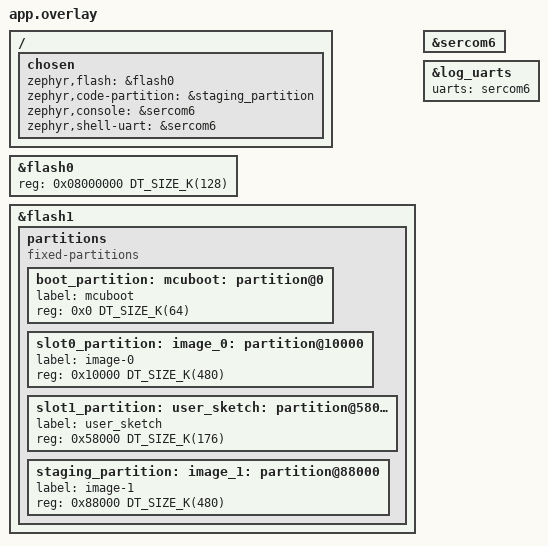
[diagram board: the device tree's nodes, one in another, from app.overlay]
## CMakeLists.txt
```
# SPDX-License-Identifier: Apache-2.0

cmake_minimum_required(VERSION 3.20.0)

# Resolve NORMALIZED_BOARD_TARGET so the board variant overlay can be named.
#
# Both overlays are listed explicitly, variant first, so app.overlay is last and
# therefore wins: the variants set `chosen { zephyr,console = ... }` themselves
# (sercom6 on both assemblies) and this sample restates it rather than relying
# on that. Ordering here is plain list order -- deliberately not the
# DTC_OVERLAY_FILE-vs-EXTRA_DTC_OVERLAY_FILE concatenation detail, which is an
# undocumented Zephyr implementation detail that fails silently if it changes.
find_package(Zephyr REQUIRED HINTS $ENV{ZEPHYR_BASE} COMPONENTS yaml boards)
set(DTC_OVERLAY_FILE
	${CMAKE_CURRENT_LIST_DIR}/../../variants/${NORMALIZED_BOARD_TARGET}/${NORMALIZED_BOARD_TARGET}.overlay
	${CMAKE_CURRENT_LIST_DIR}/app.overlay
)

find_package(Zephyr REQUIRED HINTS $ENV{ZEPHYR_BASE})
project(usb-dfu)

include(${ZEPHYR_BASE}/samples/subsys/usb/common/common.cmake)
FILE(GLOB app_sources src/*.c)
target_sources(app PRIVATE ${app_sources})

# <dfu_cookie.h> - the address/magic contract this sample shares with the
# loader and sketch. It lives beside the overlay that declares the reserved
# region so the two can never drift apart. The variants directory is not
# otherwise on the include path here: the core's top-level CMakeLists adds it,
# but only when CONFIG_ARDUINO_API is set, which this sample deliberately does
# not enable.
target_include_directories(app PRIVATE
	${CMAKE_CURRENT_LIST_DIR}/../../variants/arduino_nano_xl_link_pic32ck1025gc01144
	${CMAKE_CURRENT_LIST_DIR}/../../loader/boards/arduino_nano_xl_link_pic32ck1025gc01144/bfm
)

# The BFM writer and the Dual-Boot slot management moved to loader/boards/ so
# the loader can use them too - they are SoC behaviour, not sample behaviour.
# (They are NOT under variants/: arduino-cli scans that directory recursively
# when building a sketch, so anything there is compiled into every sketch.)
# They are added here rather than guarded internally, so "is this file in this
# image" is a build-system question.
target_sources_ifdef(CONFIG_APP_BFM_FLASH app PRIVATE
	${CMAKE_CURRENT_LIST_DIR}/../../loader/boards/arduino_nano_xl_link_pic32ck1025gc01144/bfm/bfm_flash.c
	${CMAKE_CURRENT_LIST_DIR}/../../loader/boards/arduino_nano_xl_link_pic32ck1025gc01144/bfm/bfm_boot.c
)
```

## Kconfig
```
# Copyright (c) 2023 Nordic Semiconductor ASA
# SPDX-License-Identifier: Apache-2.0

menu "USB DFU sample options"

config APP_USB_DFU_USE_FLASH_BACKEND
	select FLASH
	select FLASH_MAP
	select STREAM_FLASH
	select IMG_MANAGER
	select IMG_ERASE_PROGRESSIVELY
	bool "Option to clear the flash area before mounting"
	help
	  Use this to force an existing file system to be created.

if APP_USB_DFU_USE_FLASH_BACKEND

config USBD_DFU_FLASH
	default y

config USBD_DFU_FLASH_SLOT0
	default y

config USBD_DFU_FLASH_SLOT1
	default y

endif

config APP_BFM_FLASH
	bool
	help
	  Build src/bfm_flash.c, the on-chip writer for the Boot Flash Memory at
	  0x08000000. No prompt: it is selected by whatever needs it, and there
	  is nothing to gain from turning it on alone.

config APP_BFM_SELFTEST
	bool "Self-test the on-chip BFM writer at boot"
	select APP_BFM_FLASH
	select PRINTK
	select CONSOLE
	select UART_CONSOLE
	help
	  Program two scratch BFM pages from the running image at boot and
	  report on sercom6 (header J4, TX=PA00/RX=PA01) at 115200, proving that
	  BFM can be written with no SWD probe attached.

	  Both write-protect registers are exercised: one page in Lower Boot
	  (LBWP) and one in Upper Boot (UBWP). Neither page is part of this
	  image, so a failure destroys nothing -- but read the pages back from
	  the host before believing the console, because a silently dropped
	  write is exactly what this is testing for.

	  Development aid. Leave it off in anything you flash to a user's board.

config APP_BFM_DFU_ALT
	bool "Expose the spare BFM slot as a DFU alternate setting"
	default y
	select APP_BFM_FLASH
	help
	  Add alternate setting 2, "bfm_spare", so this bootloader can be
	  updated over USB with no SWD probe:

	      dfu-util -a 2 -D dfu_boot.bin

	  The image is written to the Dual-Boot slot that is NOT running, at
	  0x08010000, then verified and promoted by raising its sequence number
	  so the Boot ROM maps it to 0x08000000 at the next reset. A failure at
	  any point before that promotion leaves the board booting exactly what
	  it booted before.

	  The image must fit the 64 KB slot, and it must be linked for
	  0x08000000 -- which is where it will run once promoted, not where it
	  is written.

config APP_BFM_AB_TEST
	bool "Promote the spare BFM slot at boot (destructive, dev only)"
	select APP_BFM_FLASH
	help
	  At boot, if the spare BFM slot at 0x08010000 holds a valid-looking
	  image, raise its Dual-Boot sequence number so the Boot ROM maps it to
	  0x08000000 on the next reset. This is the real promotion path, run
	  unconditionally -- it exists to prove the swap on hardware.

	  Flash this build into the ACTIVE slot and a plain build into the
	  spare. After one reset the plain build runs and nothing promotes
	  again. Putting this build in BOTH slots makes the board ping-pong
	  between them forever.

	  It rewrites a CFM User CFG page, which also carries WDT and ECC
	  configuration. Never enable it in anything you ship.

endmenu

# Source common USB sample options used to initialize new experimental USB
# device stack. The scope of these options is limited to USB samples in project
# tree, you cannot use them in your own application.
source "samples/subsys/usb/common/Kconfig.sample_usbd"

source "Kconfig.zephyr"
```

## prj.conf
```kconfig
# ---------------------------------------------------------------------------
# USB DFU bootloader -- core function
# ---------------------------------------------------------------------------
CONFIG_SERIAL=y
CONFIG_USB_DEVICE_STACK_NEXT=y
CONFIG_USB_DEVICE_PRODUCT="Arduino Nano XL Link"
CONFIG_USB_DEVICE_MANUFACTURER="Arduino"
CONFIG_USB_DEVICE_VID=0x2341
CONFIG_USB_DEVICE_PID=0x007e
CONFIG_CDC_ACM_SERIAL_INITIALIZE_AT_BOOT=n
CONFIG_CDC_ACM_SERIAL_ENABLE_AT_BOOT=n
CONFIG_USBD_DFU=y
CONFIG_APP_USB_DFU_USE_FLASH_BACKEND=y
# src/dfu_images.c is an app-local copy of the in-tree flash backend that also
# feeds dfu_activity_notify(); see the comment at the top of that file. Only one
# of the two may register slot0_image/slot1_image.
CONFIG_USBD_DFU_FLASH=n
CONFIG_USBD_DFU_FLASH_SLOT0=n
CONFIG_USBD_DFU_FLASH_SLOT1=n

# ---------------------------------------------------------------------------
# Image placement: this image links at the BFM base (0x08000000) directly --
# see app.overlay.
# ---------------------------------------------------------------------------
# Its vector table is therefore already on the hardware reset address, so
# relocating rom_start there would collide with the image itself.
#
# Per-image override on purpose; do NOT try to hoist it into the SoC
# Kconfig.defconfig, which has `default n if BOOTLOADER_MCUBOOT || MCUBOOT`.
# That default is correct for Microchip's layout, where MCUboot lives in BFM at
# flash0 offset 0 (so it already owns the reset vector) and images under it are
# chainloaded from PFM. This board deviates -- MCUboot sits in PFM and needs
# =y for a BFM stub (see extra/mcuboot/nano_xl_link_monica.conf), while this
# sample *is* the BFM resident and needs =n. "Which image owns 0x08000000" is
# genuinely a per-image fact here, so it belongs in each image's own conf.
CONFIG_ROMSTART_RELOCATION_ROM=n
CONFIG_USE_DT_CODE_PARTITION=n

# Bound the image to ONE Dual-Boot slot, not the whole 128 KB of BFM.
#
# BFM is two 64 KB slots, one per panel, and the Boot ROM maps the one with the
# higher sequence number to 0x08000000 (DS 31.2.17.2). That is what makes the
# probe-less self-update in CONFIG_APP_BFM_DFU_ALT safe against power loss --
# but it only works while the image fits a single slot. An image spanning both
# would overwrite the spare copy it is supposed to fall back on.
#
# This is deliberately enforced by the linker rather than a build-time check:
# overflowing it must fail here, loudly, and not at promotion time on a user's
# board. If it ever does overflow, shrink the image; do not raise this.
CONFIG_FLASH_LOAD_SIZE=0x10000

# ---------------------------------------------------------------------------
# Stack and buffer sizing -- NOT optional. These fix real DFU download
# failures, and they are deliberately sized for the worst case of the debug
# block at the bottom being ENABLED, so turning logging on needs no retuning.
# ---------------------------------------------------------------------------

# The DFU download handler runs on the USB device stack thread, not main:
# dfu_flash_write() -> flash_img_buffered_write() -> stream_flash_erase_to_append()
# -> flash_mchp_erase() -> exec_flash_operation() all nest there, and with
# CONFIG_LOG_MODE_IMMEDIATE every log line adds a blocking formatter frame on top.
# The 1024 B default overflows on the first erase (USAGE FAULT / stack overflow),
# which surfaces to the host as a mid-transfer dfu-util "dfuERROR / errUNKNOWN"
# at a random offset.
CONFIG_USBD_THREAD_STACK_SIZE=4096

# Total memory for ALL UDC request buffers (not per-buffer). The 1024 B default
# holds only two 512 B DFU control transfers, so while the usbd thread is
# blocked in a 4 KB page erase the next transfer's net_buf_alloc_len(K_NO_WAIT)
# fails and that DNLOAD is dropped outright -- the class never sees it, and the
# following block trips the sequence check in dfu_flash_write() ("expected N,
# got N+1"). Sized here for 16 x 512 B in flight.
CONFIG_UDC_BUF_POOL_SIZE=8192

# main() does not bring USB up (that happens in switch_to_dfu_mode(), on the
# system workqueue), so its deepest frame is the LOG_MODE_IMMEDIATE cbprintf
# path -- well under 1 KB. The upstream 32768 was 55% of all RAM this image
# used; 8192 keeps ~8x headroom. Validate with CONFIG_THREAD_ANALYZER if you
# change what main() does.
CONFIG_MAIN_STACK_SIZE=8192

# The workqueue is where switch_to_dfu_mode() actually runs -- usbd_add_descriptor
# /add_configuration/register_class/init/enable, each with blocking IMMEDIATE log
# frames on top. The 1024 B default is the same too-small-for-USB-DFU trap that
# bit USBD_THREAD_STACK_SIZE above; it has not overflowed here, this is headroom.
CONFIG_SYSTEM_WORKQUEUE_STACK_SIZE=2048

# ---------------------------------------------------------------------------
# Debug console and logging -- OPTIONAL, disabled by default.
#
# Uncomment this whole block to get the boot log on sercom6 (header J4,
# TX=PA00/RX=PA01) at 115200. See app.overlay for why sercom6 and not the
# variants' own console.
#
# Two things to know before enabling:
#
#  - Log volume perturbs DFU transfer timing. With LOG_MODE_IMMEDIATE every
#    line is a *blocking* UART write, and usbd_dfu/dfu_flash log per 512 B
#    block (~58 ms each) on the usbd thread, stalling control responses until
#    dfu-util retries a block and trips the silent sequence check
#    `data->last_block + 1U != block` in dfu_flash_write(). That is why the
#    per-module levels below are pinned at WRN rather than left at default.
#    Raise them only to debug, and expect timing to shift when you do.
#  - Historically, *disabling* logging appeared to break DFU downloads. That
#    was the USBD_THREAD_STACK_SIZE / UDC_BUF_POOL_SIZE bugs above being
#    masked by the delay log writes introduced; both are fixed now. Still
#    worth re-running one full `dfu-util` download after flipping this block,
#    since it does change transfer timing.
# ---------------------------------------------------------------------------
#CONFIG_PRINTK=y
#CONFIG_UART_LINE_CTRL=y
#CONFIG_LOG=y
#CONFIG_LOG_BACKEND_UART=y
#CONFIG_LOG_BACKEND_UART_AUTOSTART=y
#CONFIG_LOG_DEFAULT_LEVEL=3
#CONFIG_LOG_MODE_IMMEDIATE=y
#CONFIG_USBD_LOG_LEVEL_WRN=y
#CONFIG_USBD_DFU_LOG_LEVEL_WRN=y
#CONFIG_UDC_DRIVER_LOG_LEVEL_WRN=y
#CONFIG_IMG_MANAGER_LOG_LEVEL_WRN=y
#CONFIG_STREAM_FLASH_LOG_LEVEL_WRN=y
# The NVM controller reports failures as per-flag LOG_ERR in
# exec_flash_operation() (WPERR/WRERR/FIFOERR/BUSERR/OPERR/...), plus LOG_WRN
# from fcw_ready_wait() on a busy-poll timeout. INF surfaces all of those, and
# they are rare enough not to perturb transfer timing.
#CONFIG_FLASH_LOG_LEVEL_INF=y
# So a fault report names the thread instead of "unknown".
#CONFIG_THREAD_NAME=y

#override values from zephyr/samples/subsys/usb//common/Kconfig.sample_usbd
CONFIG_SAMPLE_USBD_VID=0x2341
CONFIG_SAMPLE_USBD_PID=0x007e
CONFIG_SAMPLE_USBD_PRODUCT="Arduino Nano XL Link"
CONFIG_SAMPLE_USBD_MANUFACTURER="Arduino"
```

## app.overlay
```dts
/*
 * Copyright (c) 2024 Nordic Semiconductor ASA
 *
 * SPDX-License-Identifier: Apache-2.0
 */

/*
 * dfu_boot runs from BFM (Boot Flash Memory) at 0x08000000, the SoC's true
 * hardware reset address; PFM (flash1) holds only what it chainloads.
 *
 * Two constraints make this look odd, both deliberate:
 *
 * - flash0 gets `reg` narrowed but NO `compatible`. The SoC dtsi declares it
 *   spanning 66560K (BFM + unimplemented gap + PFM) -- also the source of the
 *   "65 MB ROMSTART_REGION" in build output -- and the board dtsi deletes its
 *   `compatible` because flash_mchp_nvmctrl_g3.c is a singleton keyed on
 *   DT_INST(0, soc_nv_flash): giving BFM that compatible would make it
 *   instance 0 and aim the one flash driver at BFM, breaking the PFM writes
 *   dfu_boot exists to perform. Linking needs only `reg`.
 *
 *   Narrow it HERE and not in the SoC dtsi. That wide span is deliberate
 *   upstream design, not a defect: Microchip's own pic32ck_{gc01,sg01}_cult
 *   boards put partitions under flash0 at child offset 0x4000000, using its
 *   `ranges` to reach PFM so MCUboot can span BFM+PFM through one flash
 *   device. Narrowing it at SoC level would move their slot0/slot1/storage
 *   outside flash0's reg. This board deviates from that model (separate
 *   flash1 for PFM), so the narrowing has to be app-local.
 * - No `partitions` under flash0 either: flash_map_default.c emits a device
 *   reference per fixed-partitions parent, so a partition on a
 *   compatible-less node fails to link. Hence USE_DT_CODE_PARTITION=n and
 *   load offset 0 place the image (see prj.conf).
 */
&flash0 {
	reg = <0x08000000 DT_SIZE_K(128)>;
};

/*
 * Mirrors the PFM layout in
 * variants/arduino_nano_xl_link_pic32ck1025gc01144-common.overlay; keep the
 * two in sync. dfu_boot itself still runs from BFM and is unaffected by any of
 * this - what changes is only what its DFU alt-settings point at.
 *
 * The boot chain is now dfu_boot (BFM) -> MCUboot (0x0C000000) -> the combined
 * loader+sketch image in slot0. dfu_boot chainloads whatever `slot0_partition`
 * names, so pointing that label at the mcuboot region is what makes MCUboot the
 * second stage - there is no separate jump-address setting.
 *
 * Resulting alt-settings (order matters - see dfu_images.c):
 *
 *   alt 0  image_0    480K  the loader, as a signed MCUboot image
 *   alt 1  user_sketch 176K ordinary `arduino-cli upload` target
 *   alt 2  BFM spare   64K  dfu_boot updating itself (bfm_flash.c, not a partition)
 *   alt 3  staging    480K  a full loader+sketch bundle, for MCUboot to swap in
 *
 * alt 3 is what makes the A/B path testable without a probe and without the
 * network: push a bundle into the secondary slot over USB, mark it pending,
 * reset, and MCUboot does the swap.
 *
 * 🔴 alt 0 must stay the LOADER, not mcuboot. boards.txt's upload recipe writes
 * firmwares/zephyr-<variant>.bin to alt 0 whenever the board's loader version
 * differs from the platform's, so pointing alt 0 anywhere else makes an ordinary
 * `arduino-cli upload` push a 250 KB loader into whatever partition is there.
 * Aiming it at the 64 KB mcuboot region failed at exactly 63488 bytes.
 *
 * That is why the chainload target is boot_partition and NOT slot0_partition:
 * those two were the same node until MCUboot became the second stage, and
 * dfu_boot must now jump to mcuboot while alt 0 still addresses the loader.
 * mcuboot itself has no alt - like dfu_boot before it, it is flashed once over
 * SWD (extra/flash_pfm_pyocd.py) and is not expected to change in the field.
 */
&flash1 {
	/delete-node/ partitions;

	partitions {
		compatible = "fixed-partitions";
		#address-cells = <1>;
		#size-cells = <1>;

		boot_partition: mcuboot: partition@0 {
			label = "mcuboot";
			reg = <0x0 DT_SIZE_K(64)>;
		};

		slot0_partition: image_0: partition@10000 {
			label = "image-0";
			reg = <0x10000 DT_SIZE_K(480)>;
		};

		/*
		 * A window into the middle of MCUboot's primary slot, not a
		 * region of its own - the sketch ships inside the combined
		 * image. Page-aligned so it stays independently erasable.
		 */
		slot1_partition: user_sketch: partition@58000 {
			label = "user_sketch";
			reg = <0x58000 DT_SIZE_K(176)>;
		};

		staging_partition: image_1: partition@88000 {
			label = "image-1";
			reg = <0x88000 DT_SIZE_K(480)>;
		};
	};
};

/ {
	chosen {
		/* Link/run from BFM -- see &flash0 above. */
		zephyr,flash = &flash0;
		/*
		 * Must be a PFM partition and must be set explicitly: it no longer
		 * places the image, but subsys/dfu/boot/mcuboot.c (via IMG_MANAGER)
		 * needs ACTIVE_SLOT_FLASH_AREA_ID to compile, and flash0 can carry
		 * no partitions. Left unset it would default to the board dtsi's
		 * &slot0_partition -- which is now the mcuboot region -- so any
		 * img_manager boot_* write would land on the second-stage bootloader.
		 *
		 * This used to aim at the dead first 256 KB, which no longer exists:
		 * the A/B layout allocates all 1024 KB. The staging slot is now the
		 * least harmful target - a stray write there corrupts a downloadable
		 * OTA image, whereas every other region is either running code or the
		 * user's sketch.
		 */
		zephyr,code-partition = &staging_partition;
	};
};

/*
 * Debug console: sercom6 (user header J4, TX=PA00 / RX=PA01).
 *
 * This restates the variants' own `zephyr,console`, which is why CMakeLists.txt
 * lists the variant overlay *before* this file -- see there. Both variants
 * already put the console here, so this is a no-op on them; it is spelled out
 * so the sample keeps a usable console on any board whose variant does not.
 *
 * sercom6 is the port to use because it behaves identically on both
 * assemblies: sercom1 (J3) is hard-wired to the ESP8266 AT UART on the Monica
 * carrier, and USB CDC (board_cdc_acm_uart) is absent for exactly the part of
 * boot that needs to be observable here -- this sample boots with CDC ACM not
 * initialized and then reconfigures the USB device into DFU descriptors.
 */

/*
 * Safety net for a variant that defers sercom6 (the Arduino core opens deferred
 * peripherals on demand as `Serial` objects). A deferred device is skipped by
 * SYS_INIT, so the console driver would attach to an uninitialised UART and
 * print nothing. The Nano XL Link variants do not defer it; deleting an absent
 * property is harmless.
 */
&sercom6 {
	/delete-property/ zephyr,deferred-init;
};

/*
 * Retarget the `zephyr,log-uart` multi-backend node too, or LOG_* output keeps
 * going to the variant's port while printk() alone moves.
 */
&log_uarts {
	uarts = <&sercom6>;
};

/ {
	chosen {
		zephyr,console = &sercom6;
		/* Retargeted too, so a shell can never fall back to the old port. */
		zephyr,shell-uart = &sercom6;
	};
};
```

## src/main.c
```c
/*
 * Copyright (c) 2024 Nordic Semiconductor ASA
 *
 * SPDX-License-Identifier: Apache-2.0
 */

#include <zephyr/kernel.h>
#include <zephyr/init.h>
#include <zephyr/devicetree.h>
#include <zephyr/drivers/gpio.h>
#include <zephyr/usb/usbd.h>
#include <zephyr/usb/class/usbd_dfu.h>
#include <zephyr/dfu/mcuboot.h>
#include <zephyr/drivers/hwinfo.h>
#include <zephyr/sys/sys_io.h>
#include <zephyr/drivers/timer/system_timer.h>
#include <cmsis_core.h>
#include <zephyr/irq.h>
#include <zephyr/logging/log.h>
#include <dfu_cookie.h>
#include <pfswap.h>
#include <dfu_usb_detach.h>
#include "dfu_images.h"
#ifdef CONFIG_APP_BFM_SELFTEST
#include "bfm_selftest.h"
#endif
#ifdef CONFIG_APP_BFM_AB_TEST
#include "bfm_ab_test.h"
#endif
LOG_MODULE_REGISTER(main, LOG_LEVEL_INF);

struct arm_vector_table {
    uint32_t msp;
    uint32_t reset;
};

/* DFU_DOUBLE_RESET_MAGIC and the cookie's storage now come from
 * <dfu_cookie.h>, shared with the loader/sketch side. */

/*
 * How long a normal (non-double-tap) boot holds the window open before
 * disarming. This only bounds the *maximum* gap between the two taps; the
 * minimum is set by how early the cookie gets armed - see
 * dfu_double_reset_arm() below.
 *
 * main() blocks for this on *every* normal boot before chainloading, and it
 * dwarfs everything else dfu_boot does (reaching main() takes well under 5 ms,
 * and the app-present check microseconds), so it is effectively this
 * bootloader's entire contribution to time-to-sketch. 350 ms covers a human
 * double-tap, which is ~100-350 ms; it no longer has to absorb the tens of
 * milliseconds of "dead zone" slack the old main()-time arming needed, because
 * the cookie is now armed from the very first entry in the init table.
 *
 * Raise it if double-taps start getting missed - that is the trade being made
 * here, since a gap longer than this falls through to the chainload instead.
 */
#define DFU_DOUBLE_RESET_WINDOW_MS 350U
#define DFU_MODE_SWITCH_DELAY_MS   250U
/*
 * Reboot into the freshly written image once DFU traffic goes quiet, so the
 * arduino-cli recipe needs no host-issued reset: dfu-util's `--reset` returns
 * the raw libusb NOT_FOUND from libusb_reset_device() and exits 251, which
 * arduino-cli reports as a failed upload.
 *
 * Rescheduled from dfu_activity_notify() on every transfer, not just on
 * completion - see src/dfu_images.c.
 */
#define DFU_IDLE_REBOOT_MS         3000U
#define APP_EMPTY_WORD             0xFFFFFFFFU

/*
 * Where the next boot stage lives: boot_partition, i.e. MCUboot.
 *
 * Derived from devicetree rather than hardcoded. It used to be a literal
 * 0x0C040000; when the partition table moved to make room for the A/B slots the
 * literal kept pointing into what had become the middle of the loader image, the
 * vector-table check failed, and the board sat in DFU mode with nothing
 * obviously wrong.
 *
 * Deliberately NOT slot0_partition, which is the other thing it could plausibly
 * be. Those were the same node until MCUboot became the second stage. They have
 * to differ now: dfu_boot must jump to mcuboot, while slot0_partition stays the
 * loader so DFU alt 0 keeps addressing what boards.txt expects to write there.
 */
#define APP_BOOT_BASE \
	(DT_REG_ADDR(DT_GPARENT(DT_NODELABEL(boot_partition))) + \
	 DT_REG_ADDR(DT_NODELABEL(boot_partition)))
#define APP_VECTOR_TABLE_ADDR      ((uint32_t)APP_BOOT_BASE)

/*
 * The cookie itself lives in the DFU_COOKIE reserved-memory region (see
 * <dfu_cookie.h>), not in this image's .noinit, so that a running loader or
 * sketch can arm it too - that is what makes a USB DFU detach request land
 * here in DFU mode instead of chainloading straight past it.
 */
static bool dfu_double_reset_latched;

/*
 * Everything between the reset itself and the moment this cookie gets armed
 * is a dead zone: a second physical reset landing in it finds an unarmed
 * cookie and goes undetected, so the user has to deliberately wait before
 * tapping again. Keeping that zone as short as possible is the whole game,
 * so the arm/check runs from PRE_KERNEL_1 priority 0 - the earliest hook the
 * kernel offers, right after the C runtime is up (BSS zeroed, .data copied;
 * the DFU_COOKIE region is outside both, which is what lets the cookie
 * survive) and well before console/UART/USB/driver init.
 *
 * Doing this from main() instead - as this sample originally did, even with
 * the check hoisted to the very first statement - leaves tens of
 * milliseconds of dead zone: driver and console bring-up, plus every boot
 * log line, since CONFIG_LOG_MODE_IMMEDIATE makes each one a *blocking*
 * UART write. That is why this sample's README used to tell users the second
 * tap "shall be done slightly later than the usual double-tap interval, due
 * to Zephyr boot timing"; with the arm moved here, an ordinary fast
 * double-tap works.
 */
static int dfu_double_reset_arm(void)
{
	dfu_double_reset_latched = (DFU_COOKIE == DFU_DOUBLE_RESET_MAGIC);

	/* Arm for the next boot (or disarm, if this *is* the second tap). The
	 * window is held open, and the cookie finally cleared, back in main()
	 * once the kernel can actually wait. */
	DFU_COOKIE = dfu_double_reset_latched ? 0U : DFU_DOUBLE_RESET_MAGIC;

	return 0;
}
SYS_INIT(dfu_double_reset_arm, PRE_KERNEL_1, 0);

static const struct gpio_dt_spec led0 = GPIO_DT_SPEC_GET_OR(DT_ALIAS(led0), gpios, {0});
static bool led0_ready;
static bool dfu_download_completed;
static struct usbd_context *dfu_pending_ctx;
static void dfu_mode_work_handler(struct k_work *work);
static void dfu_reboot_work_handler(struct k_work *work);
static void schedule_dfu_mode(struct usbd_context *const ctx);
K_WORK_DELAYABLE_DEFINE(dfu_mode_work, dfu_mode_work_handler);
K_WORK_DELAYABLE_DEFINE(dfu_reboot_work, dfu_reboot_work_handler);

USBD_DEVICE_DEFINE(dfu_usbd, DEVICE_DT_GET(DT_NODELABEL(zephyr_udc0)), 0x2341, 0x017e);

USBD_DESC_LANG_DEFINE(sample_lang);
USBD_DESC_CONFIG_DEFINE(fs_cfg_desc, "DFU FS Configuration");
USBD_DESC_CONFIG_DEFINE(hs_cfg_desc, "DFU HS Configuration");

static const uint8_t attributes =
	(IS_ENABLED(CONFIG_SAMPLE_USBD_SELF_POWERED) ? USB_SCD_SELF_POWERED : 0) |
	(IS_ENABLED(CONFIG_SAMPLE_USBD_REMOTE_WAKEUP) ? USB_SCD_REMOTE_WAKEUP : 0);
/* Full speed configuration */
USBD_CONFIGURATION_DEFINE(sample_fs_config, attributes, CONFIG_SAMPLE_USBD_MAX_POWER, &fs_cfg_desc);

/* High speed configuration */
USBD_CONFIGURATION_DEFINE(sample_hs_config, attributes, CONFIG_SAMPLE_USBD_MAX_POWER, &hs_cfg_desc);

static void switch_to_dfu_mode(struct usbd_context *const ctx);

static void setup_led(void)
{
	if (!gpio_is_ready_dt(&led0)) {
		LOG_WRN("LED not available");
		return;
	}

	if (gpio_pin_configure_dt(&led0, GPIO_OUTPUT_INACTIVE)) {
		LOG_WRN("Failed to configure LED");
		return;
	}

	led0_ready = true;
}

/*
 * led0 is a plain GPIO (no PWM timer wired to it), so a smooth breathing fade
 * is faked with software PWM: toggle the pin at a fixed carrier with a duty
 * cycle that ramps up and back down.
 *
 * The waits are k_usleep(), not k_busy_wait(). Busy-waiting works -- the usbd
 * thread (coop prio -8) and the system workqueue (-1) both preempt main (prio
 * 0), so DFU is unaffected either way -- but it pegs the core at 100% for the
 * whole, indefinite DFU residency and never lets the idle thread reach WFI.
 * Sleeping costs ~500 context switches/s instead, i.e. well under 1% CPU.
 *
 * STEPS is tick-aligned deliberately: CONFIG_SYS_CLOCK_TICKS_PER_SEC=10000
 * gives a 100 us tick and CARRIER_US / STEPS == 100 us, so every sleep is a
 * whole number of ticks. Finer steps than the tick would just round, distorting
 * the dim end of the ramp.
 */
#define DFU_BREATH_STEPS      40U   /* brightness levels per ramp (100 us each) */
#define DFU_BREATH_CARRIER_US 4000U /* soft-PWM carrier period (250 Hz) */
#define DFU_BREATH_REPS       3U    /* carrier periods per step, so 12 ms each */

static FUNC_NORETURN void breathe_led_forever(void)
{
	if (!led0_ready) {
		while (true) {
			k_sleep(K_FOREVER);
		}
	}

	while (true) {
		/*
		 * Triangle ramp: phase 0..STEPS fades in, STEPS..2*STEPS fades
		 * back out, so one full cycle is
		 * 2 * STEPS * REPS * CARRIER_US = 80 * 3 * 4 ms ~= 0.96 s.
		 */
		for (uint32_t phase = 0; phase < 2U * DFU_BREATH_STEPS; phase++) {
			uint32_t level = (phase < DFU_BREATH_STEPS)
						 ? phase
						 : (2U * DFU_BREATH_STEPS - phase);
			uint32_t on_us = (DFU_BREATH_CARRIER_US * level) / DFU_BREATH_STEPS;
			uint32_t off_us = DFU_BREATH_CARRIER_US - on_us;

			for (uint32_t rep = 0; rep < DFU_BREATH_REPS; rep++) {
				if (on_us > 0U) {
					(void)gpio_pin_set_dt(&led0, 1);
					k_usleep(on_us);
				}
				if (off_us > 0U) {
					(void)gpio_pin_set_dt(&led0, 0);
					k_usleep(off_us);
				}
			}
		}
	}
}

static void dfu_mode_work_handler(struct k_work *work)
{
	ARG_UNUSED(work);

	switch_to_dfu_mode(dfu_pending_ctx);
	dfu_pending_ctx = NULL;
}

static void schedule_dfu_mode(struct usbd_context *const ctx)
{
	dfu_pending_ctx = ctx;
	(void)k_work_reschedule(&dfu_mode_work, K_MSEC(DFU_MODE_SWITCH_DELAY_MS));
}

static void dfu_reboot_work_handler(struct k_work *work)
{
	ARG_UNUSED(work);

	if (!dfu_download_completed) {
		/* Traffic without a completed download: nothing new to boot. */
		return;
	}

	LOG_INF("Resetting MCU after DFU transfer");
	dfu_usb_soft_disconnect();
	(void)irq_lock();
	NVIC_SystemReset();
	CODE_UNREACHABLE;
}

void dfu_activity_notify(void)
{
	/* Push the reboot out on every transfer, so it can only fire once the
	 * host has finished with us. */
	(void)k_work_reschedule(&dfu_reboot_work, K_MSEC(DFU_IDLE_REBOOT_MS));
}

/*
 * Undo the PFM panel swap the Boot ROM performs alongside the BFM one.
 *
 * The register sequence and the reasoning live in the variant's pfswap.h,
 * shared with extra/mcuboot/hooks rather than copied: both bootloaders in this
 * tree need it, and a correction to undocumented SoC behaviour landing in only
 * one of them is exactly the kind of drift that ends in a board that will not
 * boot.
 *
 * This is safe here and nowhere later: changing PFSWAP requires that nothing is
 * accessing either PFM panel (DS 31.2.17.4). This image lives entirely in BFM,
 * so the first PFM access in the whole program is app_image_present() below.
 */
static void normalize_pfswap(void)
{
	switch (pfm_normalize_swap()) {
	case PFM_SWAP_NORMALIZED:
		LOG_INF("PFSWAP normalized");
		break;
	case PFM_SWAP_LOCKED:
		LOG_ERR("PFSWAP set and locked; PFM addresses stay shifted");
		break;
	case PFM_SWAP_FAILED:
		LOG_ERR("PFSWAP would not clear");
		break;
	case PFM_SWAP_ALREADY_NORMAL:
		break;
	}
}

static bool app_image_present(uint32_t vector_addr)
{
    uint32_t initial_msp = sys_read32(vector_addr);
    uint32_t reset_vector = sys_read32(vector_addr + sizeof(uint32_t));
    uint32_t reset_pc = reset_vector & ~BIT(0);

    uintptr_t slot_base = APP_BOOT_BASE;
    uintptr_t slot_end = slot_base + DT_REG_SIZE(DT_NODELABEL(boot_partition));

    /* VTOR on Cortex-M needs alignment on 128-byte boundary */
    if ((vector_addr & 0x7FU) != 0U) {
        return false;
    }

    /* MSP must be valid pointer and 8-byte aligned */
    if ((initial_msp == 0U) || (initial_msp == APP_EMPTY_WORD)) {
        return false;
    }
    if ((initial_msp & 0x7U) != 0U) {
        return false;
    }

    /* Reset vector must be Thumb and point inside loader slot */
    if ((reset_vector & BIT(0)) == 0U) {
        return false;
    }
    if ((reset_pc < slot_base) || (reset_pc >= slot_end)) {
        return false;
    }

    /* First instruction at reset handler must not be erased/zero */
    uint32_t first_instr = sys_read32(reset_pc);
    if ((first_instr == 0U) || (first_instr == APP_EMPTY_WORD)) {
        return false;
    }

    return true;
}

static FUNC_NORETURN void jump_to_application(uint32_t app_addr)
{
	struct arm_vector_table *vt = (struct arm_vector_table *)app_addr;

	/* 1. Disable and clear pending state for all NVIC lines. */
    (void)irq_lock();

    for (int i = 0; i < (CONFIG_NUM_IRQS + 31) / 32; i++) {
        NVIC->ICER[i] = 0xFFFFFFFF;
        NVIC->ICPR[i] = 0xFFFFFFFF;
    }

	/*
	 * 1b. SysTick is a dedicated core exception, not part of the NVIC
	 * IRQ array cleared above, so it survives the loop untouched. If left
	 * running, the loader's own kernel init -- which assumes SysTick is in
	 * its power-on-reset state, not "already configured and counting by a
	 * previous image" -- can end up with a broken/mismatched tick source
	 * (observed on hardware: the loader's own uptime clock never advances
	 * after chainloading). Disable it and clear any pending SysTick
	 * exception before jumping, so the loader gets a clean slate.
	 *
	 * ICSR must be written by ASSIGNMENT, never read-modify-write: it
	 * holds write-1-to-set bits (PENDSTSET b26, PENDSVSET b28, NMIPENDSET
	 * b31), so a `|=` reads those status bits and writes them straight
	 * back, *setting* the very exceptions it means to clear. That leaves
	 * the loader starting with a spurious pending SysTick/PendSV and
	 * hanging as soon as it unmasks interrupts. On Armv8-M ICSR.STTNS is
	 * R/W and must be preserved -- this is the same idiom Zephyr's own
	 * cortex_m_systick.c uses. PendSV is cleared too: dfu_boot is a
	 * threaded Zephyr app, so a context switch may well be pending at the
	 * moment we jump.
	 *
	 * SysTick->VAL is deliberately not touched: the incoming image's
	 * sys_clock_driver_init() sets LOAD and VAL itself.
	 */
	sys_clock_disable();
#ifdef SCB_ICSR_STTNS_Msk
	SCB->ICSR = (SCB->ICSR & SCB_ICSR_STTNS_Msk) |
		    SCB_ICSR_PENDSTCLR_Msk | SCB_ICSR_PENDSVCLR_Msk;
#else
	SCB->ICSR = SCB_ICSR_PENDSTCLR_Msk | SCB_ICSR_PENDSVCLR_Msk;
#endif

	/* 2. Clear stack limits inherited from the previous context. */
	__set_MSPLIM(0U);
	__set_PSPLIM(0U);

	/* 3. Set CONTROL back to 0: privileged Thread mode, MSP selected. */
    __set_CONTROL(0);
    __ISB();

#if defined(CONFIG_ARM_MPU)
	/* 4. Disable MPU to avoid memory access faults when jumping to the loader/application. */
	MPU->CTRL = 0;
	__DSB();
	__ISB();
#endif

	/* 4. Relocate vector table to the target image . */
    SCB->VTOR = app_addr;
    __DSB();
    __ISB();

	/* 5. Load target MSP and branch to target Reset_Handler. */
    __set_MSP(vt->msp);
    __ISB();

    ((void (*)(void))vt->reset)();

    CODE_UNREACHABLE;
}

static void msg_cb(struct usbd_context *const usbd_ctx, const struct usbd_msg *const msg)
{
	LOG_INF("USBD message: %s", usbd_msg_type_string(msg->type));

	if (msg->type == USBD_MSG_CONFIGURATION) {
		LOG_INF("\tConfiguration value %d", msg->status);
	}

	if (usbd_can_detect_vbus(usbd_ctx)) {
		if (msg->type == USBD_MSG_VBUS_READY) {
			if (usbd_enable(usbd_ctx)) {
				LOG_ERR("Failed to enable device support");
			}
		}

		if (msg->type == USBD_MSG_VBUS_REMOVED) {
			if (usbd_disable(usbd_ctx)) {
				LOG_ERR("Failed to disable device support");
			}
		}
	}

	if (msg->type == USBD_MSG_DFU_APP_DETACH) {
		LOG_INF("DFU app detach received, switching USB device to DFU descriptors");
		schedule_dfu_mode(usbd_ctx);
	}

	if (msg->type == USBD_MSG_DFU_DOWNLOAD_COMPLETED) {
		LOG_INF("DFU download completed, arming reboot");
		dfu_download_completed = true;
		(void)k_work_reschedule(&dfu_reboot_work, K_MSEC(DFU_IDLE_REBOOT_MS));
	}
}

static void switch_to_dfu_mode(struct usbd_context *const ctx)
{
	int err;

	LOG_INF("Detach USB device");
	if (ctx != NULL) {
		usbd_disable(ctx);
		usbd_shutdown(ctx);
	}

	err = usbd_add_descriptor(&dfu_usbd, &sample_lang);
	if (err) {
		LOG_ERR("Failed to initialize language descriptor (%d)", err);
		return;
	}

	if (usbd_caps_speed(&dfu_usbd) == USBD_SPEED_HS) {
		err = usbd_add_configuration(&dfu_usbd, USBD_SPEED_HS, &sample_hs_config);
		if (err) {
			LOG_ERR("Failed to add High-Speed configuration");
			return;
		}

		err = usbd_register_class(&dfu_usbd, "dfu_dfu", USBD_SPEED_HS, 1);
		if (err) {
			LOG_ERR("Failed to add register classes");
			return;
		}

		usbd_device_set_code_triple(&dfu_usbd, USBD_SPEED_HS, 0, 0, 0);
	}

	err = usbd_add_configuration(&dfu_usbd, USBD_SPEED_FS, &sample_fs_config);
	if (err) {
		LOG_ERR("Failed to add Full-Speed configuration");
		return;
	}

	err = usbd_register_class(&dfu_usbd, "dfu_dfu", USBD_SPEED_FS, 1);
	if (err) {
		LOG_ERR("Failed to add register classes");
		return;
	}

	usbd_device_set_code_triple(&dfu_usbd, USBD_SPEED_FS, 0, 0, 0);

	err = usbd_init(&dfu_usbd);
	if (err) {
		LOG_ERR("Failed to initialize USB device support");
		return;
	}

	err = usbd_msg_register_cb(&dfu_usbd, msg_cb);
	if (err) {
		LOG_ERR("Failed to register message callback");
		return;
	}

	err = usbd_enable(&dfu_usbd);
	if (err) {
		LOG_ERR("Failed to enable USB device support");
	}
}

int main(void)
{
	/* Before anything reads PFM -- see the comment on the function. */
	normalize_pfswap();

	setup_led();

#ifdef CONFIG_APP_BFM_SELFTEST
	/*
	 * Before the double-reset window, so it runs on every boot including
	 * the normal one that chainloads the loader a few lines below.
	 */
	bfm_selftest();
#endif

#ifdef CONFIG_APP_BFM_AB_TEST
	bfm_ab_test();
#endif

	/* Latched at PRE_KERNEL_1 by dfu_double_reset_arm(). */
	if (dfu_double_reset_latched) {
		LOG_INF("Double reset detected, entering DFU mode");
	} else {
		/* Hold the window open for a second tap, then disarm. */
		k_msleep(DFU_DOUBLE_RESET_WINDOW_MS);
		DFU_COOKIE = 0U;
		LOG_INF("No double reset detected, exiting USB DFU sample boot...");

		if (app_image_present(APP_VECTOR_TABLE_ADDR)) {
			LOG_INF("Loader image present at 0x%08x", APP_VECTOR_TABLE_ADDR);
			jump_to_application(APP_VECTOR_TABLE_ADDR);
		}

		LOG_WRN("No valid loader image at 0x%08x", APP_VECTOR_TABLE_ADDR);
	}

	/*
	 * Both remaining paths stay resident in DFU mode. No USB context is set
	 * up here: switch_to_dfu_mode() only ever disables/shuts down whatever
	 * it is handed before building `dfu_usbd` itself, so passing NULL just
	 * skips a teardown of a context that was never created.
	 */
	schedule_dfu_mode(NULL);
	breathe_led_forever();

	return 0;
}
```

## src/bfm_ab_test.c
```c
/*
 * Copyright (c) 2026 Arduino SA
 *
 * SPDX-License-Identifier: Apache-2.0
 */

/*
 * Proof of the Dual-Boot swap: promote the spare BFM slot at boot.
 *
 * Deliberately observable without a console. The verdict is the hardware state
 * itself, readable over SWD after a reset:
 *
 *   FCW.SWAP    0x44004048  -- BFSWAP flips
 *   FSEQ0 p1    0x0A000000  -- sequence numbers
 *   FSEQ0 p2    0x0A008000
 *
 * A console would only tell you what the firmware believed. BFSWAP is what the
 * Boot ROM actually did with it.
 *
 * Setup: this build goes in the ACTIVE slot, a plain build in the spare. See
 * CONFIG_APP_BFM_AB_TEST for why that ordering matters.
 */

#include <zephyr/kernel.h>

#ifdef CONFIG_APP_BFM_AB_TEST

#include <errno.h>

#include "bfm_boot.h"
#include "bfm_flash.h"

#include "bfm_ab_test.h"

#ifdef CONFIG_PRINTK
#include <zephyr/sys/printk.h>
#define AB_PRINT(...) printk(__VA_ARGS__)
#else
#define AB_PRINT(...)
#endif

void bfm_ab_test(void)
{
	struct bfm_boot_state state;
	int ret;

	bfm_boot_get_state(&state);

	AB_PRINT("\nbfm_ab_test: BFSWAP=%u BFSLOCK=%u\n", state.bfswap, state.swap_locked);
	AB_PRINT("bfm_ab_test: active ucfg 0x%08x seq=%u valid=%u\n", state.active_ucfg,
		 state.active_seq, state.active_seq_valid);
	AB_PRINT("bfm_ab_test: spare  ucfg 0x%08x seq=%u valid=%u\n", state.spare_ucfg,
		 state.spare_seq, state.spare_seq_valid);

	if (!bfm_boot_spare_image_valid()) {
		/*
		 * Expected whenever the spare slot is blank or holds debris.
		 * Nothing is written, and the board boots as usual.
		 */
		AB_PRINT("bfm_ab_test: spare slot holds no valid image, nothing to do\n\n");
		return;
	}

	AB_PRINT("bfm_ab_test: promoting spare to seq=%u\n", state.active_seq + 1U);

	ret = bfm_boot_promote_spare();
	if (ret != 0) {
		AB_PRINT("bfm_ab_test: promote FAILED ret=%d intflag=0x%08x\n", ret,
			 bfm_last_intflag());
		return;
	}

	AB_PRINT("bfm_ab_test: promoted; the spare boots after the next reset\n\n");
}

#endif /* CONFIG_APP_BFM_AB_TEST */
```

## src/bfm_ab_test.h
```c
/*
 * Copyright (c) 2026 Arduino SA
 *
 * SPDX-License-Identifier: Apache-2.0
 */

#ifndef BFM_AB_TEST_H_
#define BFM_AB_TEST_H_

/*
 * Promote the spare BFM slot, if it holds a valid image. Only built when
 * CONFIG_APP_BFM_AB_TEST is set; see bfm_ab_test.c.
 */
void bfm_ab_test(void);

#endif /* BFM_AB_TEST_H_ */
```

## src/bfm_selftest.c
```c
/*
 * Copyright (c) 2026 Arduino SA
 *
 * SPDX-License-Identifier: Apache-2.0
 */

/*
 * Proof that BFM can be programmed by code running on this chip, with no SWD
 * probe. Enable with CONFIG_APP_BFM_SELFTEST and watch sercom6 at 115200.
 *
 * Two pages are programmed, one per write-protect register, because they are
 * genuinely separate hardware: LBWP[15:0] guards Lower Boot and UBWP[15:0]
 * guards Upper Boot, and a writer that clears only the first works perfectly
 * until an image crosses 64 KB. Upper Boot goes first -- if the very first
 * on-chip NVMOP ever attempted were to decode to the wrong address, that is the
 * half that does not contain the reset vector.
 *
 * The pattern is address-derived, so a page written to the right size but the
 * wrong offset fails the compare instead of passing it.
 *
 * The device's own verdict is not the acceptance gate. Read the pages back from
 * the host afterwards:
 *
 *   pyocd commander -t pic32ck1025sg01144 -O pack.debug_sequences.enable=false \
 *     -O connect_mode=under-reset -c "read32 0x0801F000 0x8" -c "read32 0x0800F000 0x8"
 *
 * A silently dropped write is the failure mode this whole area is built around,
 * and firmware that never noticed cannot report it.
 */

#include <zephyr/kernel.h>

#ifdef CONFIG_APP_BFM_SELFTEST

#include <errno.h>

#include <zephyr/sys/printk.h>
#include <zephyr/sys/util.h>

#include "bfm_flash.h"
#include "bfm_selftest.h"

#define SELFTEST_MAGIC 0xB1F0AA55U

/*
 * Upper Boot page 15 (0x0801F000). Blank as shipped.
 *
 * Lower Boot page 15 (0x0800F000) is past the end of this image -- dfu_boot is
 * ~56 KB and ends around 0x0800DAB8 -- but it is NOT blank: it holds debris
 * from an older, larger image that tools/chandler_flasher/chandler_flasher.py never erased,
 * because that script only erases the pages the new image covers. Erasing it
 * here is both safe and a cleanup. If dfu_boot ever grows past 60 KB, this
 * target has to move.
 */
#define SELFTEST_UPPER_PAGE (BFM_BASE + BFM_SIZE - BFM_PAGE_SIZE)
#define SELFTEST_LOWER_PAGE (BFM_BASE + BFM_LOWER_SIZE - BFM_PAGE_SIZE)

/* 4 KB, too big for a thread stack. */
static uint32_t pattern[BFM_PAGE_SIZE / sizeof(uint32_t)];

static void build_pattern(uint32_t page)
{
	for (size_t i = 0; i < ARRAY_SIZE(pattern); i++) {
		pattern[i] = SELFTEST_MAGIC ^ (page + (uint32_t)(i * sizeof(uint32_t)));
	}
}

static int run_one(const char *what, uint32_t page)
{
	int ret;

	build_pattern(page);

	printk("bfm_selftest: %s page 0x%08x: programming %u bytes\n", what, page,
	       (unsigned int)sizeof(pattern));

	ret = bfm_program(page, pattern, sizeof(pattern));
	if (ret != 0) {
		printk("bfm_selftest: %s page 0x%08x: FAILED ret=%d intflag=0x%08x\n", what, page,
		       ret, bfm_last_intflag());
		return ret;
	}

	/*
	 * bfm_program() already compared, but it compared against the same
	 * buffer it programmed from. Re-read through a volatile pointer so the
	 * compiler cannot fold this into the earlier compare.
	 */
	for (size_t i = 0; i < ARRAY_SIZE(pattern); i++) {
		volatile const uint32_t *p = (volatile const uint32_t *)(uintptr_t)page;

		if (p[i] != pattern[i]) {
			printk("bfm_selftest: %s page 0x%08x: MISMATCH at +0x%x: "
			       "read 0x%08x want 0x%08x\n",
			       what, page, (unsigned int)(i * sizeof(uint32_t)), p[i], pattern[i]);
			return -EIO;
		}
	}

	printk("bfm_selftest: %s page 0x%08x: OK (intflag=0x%08x)\n", what, page,
	       bfm_last_intflag());

	return 0;
}

void bfm_selftest(void)
{
	int upper;
	int lower;

	printk("\nbfm_selftest: on-chip BFM writer, no probe involved\n");

	upper = run_one("UBWP/upper", SELFTEST_UPPER_PAGE);
	lower = run_one("LBWP/lower", SELFTEST_LOWER_PAGE);

	printk("bfm_selftest: result upper=%s lower=%s\n", upper == 0 ? "OK" : "FAIL",
	       lower == 0 ? "OK" : "FAIL");
	printk("bfm_selftest: confirm from the host before believing this\n\n");
}

#endif /* CONFIG_APP_BFM_SELFTEST */
```

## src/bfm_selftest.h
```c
/*
 * Copyright (c) 2026 Arduino SA
 *
 * SPDX-License-Identifier: Apache-2.0
 */

#ifndef BFM_SELFTEST_H_
#define BFM_SELFTEST_H_

/*
 * Program two scratch BFM pages from the running image and report to the
 * console. Only built when CONFIG_APP_BFM_SELFTEST is set; see bfm_selftest.c.
 */
void bfm_selftest(void);

#endif /* BFM_SELFTEST_H_ */
```

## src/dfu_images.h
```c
/*
 * Copyright (c) 2025 Arduino SA
 *
 * SPDX-License-Identifier: Apache-2.0
 */

#ifndef DFU_BOOT_DFU_IMAGES_H_
#define DFU_BOOT_DFU_IMAGES_H_

/**
 * @brief Report that a DFU transfer just touched an image.
 *
 * Implemented in main.c, where it re-arms the "DFU has gone quiet, boot the new
 * image" timer.
 */
void dfu_activity_notify(void);

#endif /* DFU_BOOT_DFU_IMAGES_H_ */
```
